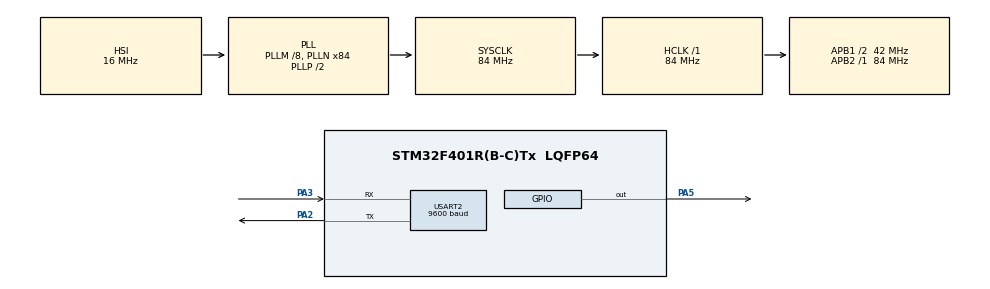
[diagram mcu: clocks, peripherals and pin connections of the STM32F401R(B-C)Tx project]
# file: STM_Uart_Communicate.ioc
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Mcu.Family=STM32F4
Mcu.Name=STM32F401R(B-C)Tx
Mcu.Package=LQFP64
NVIC.PriorityGroup=NVIC_PRIORITYGROUP_4
PA2.Mode=Asynchronous
PA2.Signal=USART2_TX
PA3.Mode=Asynchronous
PA3.Signal=USART2_RX
PA5.Signal=GPIO_Output
ProjectManager.HeapSize=0x200
ProjectManager.StackSize=0x400
ProjectManager.TargetToolchain=STM32CubeIDE
RCC.48MHZClocksFreq_Value=42000000
RCC.AHBFreq_Value=84000000
RCC.APB1CLKDivider=RCC_HCLK_DIV2
RCC.APB1Freq_Value=42000000
RCC.APB1TimFreq_Value=84000000
RCC.APB2Freq_Value=84000000
RCC.APB2TimFreq_Value=84000000
RCC.CortexFreq_Value=84000000
RCC.HCLKFreq_Value=84000000
RCC.HSE_VALUE=25000000
RCC.HSI_VALUE=16000000
RCC.LSE_VALUE=32768
RCC.PLLM=8
RCC.PLLN=84
RCC.SYSCLKFreq_VALUE=84000000
RCC.SYSCLKSource=RCC_SYSCLKSOURCE_PLLCLK
RCC.VCOOutputFreq_Value=168000000
USART2.BaudRate=9600
USART2.VirtualMode=VM_ASYNC
board=custom

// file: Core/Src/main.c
/* USER CODE BEGIN Header */
/**
  ******************************************************************************
  * @file           : main.c
  * @brief          : Main program body
  ******************************************************************************
  * @attention
  *
  * Copyright (c) 2025 STMicroelectronics.
  * All rights reserved.
  *
  * This software is licensed under terms that can be found in the LICENSE file
  * in the root directory of this software component.
  * If no LICENSE file comes with this software, it is provided AS-IS.
  *
  ******************************************************************************
  */
/* USER CODE END Header */
#include "main.h"
#include "usart.h"
#include "gpio.h"
#include <string.h> // For string handling

/* USER CODE BEGIN PV */
char rx_buffer[100]; // Buffer to store received data
uint8_t rx_index = 0; // Index for buffer
uint8_t command_received = 0; // Flag to indicate command received
/* USER CODE END PV */

void SystemClock_Config(void);
/* USER CODE BEGIN PFP */
void HAL_UART_RxCpltCallback(UART_HandleTypeDef *huart) {
  if (huart->Instance == USART2) {
    if (rx_buffer[rx_index - 1] == '\n') { // Check for newline character
      rx_buffer[rx_index - 1] = '\0'; // Replace newline with null terminator
      command_received = 1; // Set flag
    } else {
      HAL_UART_Receive_IT(&huart2, (uint8_t*)&rx_buffer[rx_index++], 1); // Continue receiving
    }
  }
}
/* USER CODE END PFP */

int main(void)
{

  /* MCU Configuration--------------------------------------------------------*/

  /* Reset of all peripherals, Initializes the Flash interface and the Systick. */
  HAL_Init();

  /* Configure the system clock */
  SystemClock_Config();

  /* Initialize all configured peripherals */
  MX_GPIO_Init();
  MX_USART2_UART_Init();
  HAL_UART_Receive_IT(&huart2, (uint8_t*)&rx_buffer[rx_index++], 1); // Start receiving

  /* Infinite loop */
  while (1)
  {
	  // Check if a command has been received
	    if (command_received) {
	      command_received = 0; // Reset flag

	      // Process the command
	           if (strcmp(rx_buffer, "LED_ON") == 0) {
	             HAL_GPIO_WritePin(GPIOA, GPIO_PIN_5, GPIO_PIN_SET); // Turn on LED
	             HAL_UART_Transmit(&huart2, (uint8_t*)"LED ON\r\n", 8, 100); // Send response
	           } else if (strcmp(rx_buffer, "LED_OFF") == 0) {
	             HAL_GPIO_WritePin(GPIOA, GPIO_PIN_5, GPIO_PIN_RESET); // Turn off LED
	             HAL_UART_Transmit(&huart2, (uint8_t*)"LED OFF\r\n", 9, 100); // Send response
	           } else {
	             HAL_UART_Transmit(&huart2, (uint8_t*)"Unknown Command\r\n", 17, 100); // Send error
	           }

	           // Clear the buffer
	           memset(rx_buffer, 0, sizeof(rx_buffer));
	           rx_index = 0;
	         }
	       }
  }

void SystemClock_Config(void)
{
  RCC_OscInitTypeDef RCC_OscInitStruct = {0};
  RCC_ClkInitTypeDef RCC_ClkInitStruct = {0};

  /** Configure the main internal regulator output voltage
  */
  __HAL_RCC_PWR_CLK_ENABLE();
  __HAL_PWR_VOLTAGESCALING_CONFIG(PWR_REGULATOR_VOLTAGE_SCALE2);

  /** Initializes the RCC Oscillators according to the specified parameters
  * in the RCC_OscInitTypeDef structure.
  */
  RCC_OscInitStruct.OscillatorType = RCC_OSCILLATORTYPE_HSI;
  RCC_OscInitStruct.HSIState = RCC_HSI_ON;
  RCC_OscInitStruct.HSICalibrationValue = RCC_HSICALIBRATION_DEFAULT;
  RCC_OscInitStruct.PLL.PLLState = RCC_PLL_ON;
  RCC_OscInitStruct.PLL.PLLSource = RCC_PLLSOURCE_HSI;
  RCC_OscInitStruct.PLL.PLLM = 8;
  RCC_OscInitStruct.PLL.PLLN = 84;
  RCC_OscInitStruct.PLL.PLLP = RCC_PLLP_DIV2;
  RCC_OscInitStruct.PLL.PLLQ = 4;
  if (HAL_RCC_OscConfig(&RCC_OscInitStruct) != HAL_OK)
  {
    Error_Handler();
  }

  /** Initializes the CPU, AHB and APB buses clocks
  */
  RCC_ClkInitStruct.ClockType = RCC_CLOCKTYPE_HCLK|RCC_CLOCKTYPE_SYSCLK
                              |RCC_CLOCKTYPE_PCLK1|RCC_CLOCKTYPE_PCLK2;
  RCC_ClkInitStruct.SYSCLKSource = RCC_SYSCLKSOURCE_PLLCLK;
  RCC_ClkInitStruct.AHBCLKDivider = RCC_SYSCLK_DIV1;
  RCC_ClkInitStruct.APB1CLKDivider = RCC_HCLK_DIV2;
  RCC_ClkInitStruct.APB2CLKDivider = RCC_HCLK_DIV1;

  if (HAL_RCC_ClockConfig(&RCC_ClkInitStruct, FLASH_LATENCY_2) != HAL_OK)
  {
    Error_Handler();
  }
}

void Error_Handler(void)
{
  __disable_irq();
  while (1)
  {
  }
}
